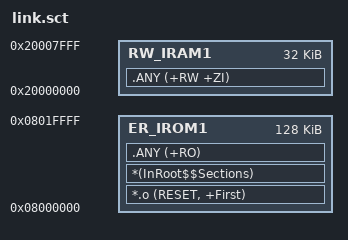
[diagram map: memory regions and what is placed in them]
; *************************************************************
; *** Scatter-Loading Description File generated by uVision ***
; *************************************************************

LR_IROM1 0x08000000 0x00020000  {    ; load region size_region (128KB flash for GD32C113VB)
  ER_IROM1 0x08000000 0x00020000  {  ; load address = execution address
   *.o (RESET, +First)
   *(InRoot$$Sections)
   .ANY (+RO)
  }
  RW_IRAM1 0x20000000 0x00008000  {  ; RW data (32KB SRAM for GD32C113VB)
   .ANY (+RW +ZI)
  }
}

